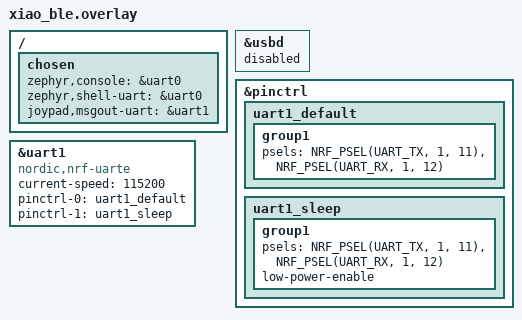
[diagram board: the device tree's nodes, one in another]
/* Joypad — Seeed XIAO nRF52840 devicetree overlay
 *
 * TinyUSB drives USB hardware directly, so disable Zephyr's USBD node.
 * Console redirected to UART0 (RTT is the actual debug output).
 */

&usbd {
	status = "disabled";
};

/ {
	chosen {
		zephyr,console = &uart0;
		zephyr,shell-uart = &uart0;
		/* Wired-UART message-output input (msgout_uart.c) — a parallel path to
		 * the BLE 6E40FE01 service. A USB-to-UART adapter writes the same ASCII
		 * button tokens on uart1 (D6 = P1.11 TX, D7 = P1.12 RX): adapter TX ->
		 * board RX (D7), adapter RX <- board TX (D6), GND common. */
		joypad,msgout-uart = &uart1;
	};
};

&pinctrl {
	uart1_default: uart1_default {
		group1 {
			psels = <NRF_PSEL(UART_TX, 1, 11)>,
				<NRF_PSEL(UART_RX, 1, 12)>;
		};
	};

	uart1_sleep: uart1_sleep {
		group1 {
			psels = <NRF_PSEL(UART_TX, 1, 11)>,
				<NRF_PSEL(UART_RX, 1, 12)>;
			low-power-enable;
		};
	};
};

&uart1 {
	compatible = "nordic,nrf-uarte";
	status = "okay";
	current-speed = <115200>;
	pinctrl-0 = <&uart1_default>;
	pinctrl-1 = <&uart1_sleep>;
	pinctrl-names = "default", "sleep";
};
